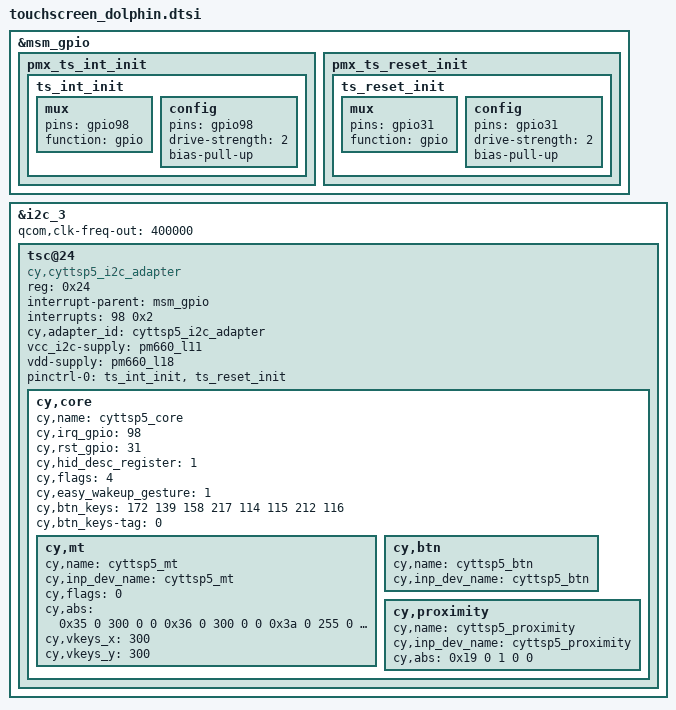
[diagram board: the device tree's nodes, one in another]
&msm_gpio {
	/* add pingrp for touchscreen */
	pmx_ts_int_init {
		ts_int_init: ts_int_init {
			mux {
				pins = "gpio98";
				function = "gpio";
			};

			config {
				pins = "gpio98";
				drive-strength = <2>;
				bias-pull-up;
			};
		};
	};

	pmx_ts_reset_init {
		ts_reset_init: ts_reset_init {
			mux {
				pins = "gpio31";
				function = "gpio";
			};

			config {
				pins = "gpio31";
				drive-strength = <2>;
				bias-pull-up;
			};
		};
	};
};

&i2c_3 {
	qcom,clk-freq-out = <400000>;
	status = "okay";

	/delete-node/ qcom,actuator@0;
	/delete-node/ qcom,eeprom@6c;
	/delete-node/ qcom,led-flash@60;
	/delete-node/ qcom,camera@0;
	/delete-node/ qcom,camera@1;
	/delete-node/ synaptics@20;

	tsc@24 {
		compatible = "cy,cyttsp5_i2c_adapter";
		reg = <0x24>;
		interrupt-parent = <&msm_gpio>;
		interrupts = <98 0x2>;
		cy,adapter_id = "cyttsp5_i2c_adapter";

		vcc_i2c-supply = <&pm660_l11>;
		vdd-supply = <&pm660_l18>;
		pinctrl-names = "pmx_ts_init";
		pinctrl-0 = <&ts_int_init &ts_reset_init>;

		cy,core {
			cy,name = "cyttsp5_core";

			cy,irq_gpio = <98>;
			cy,rst_gpio = <31>;
			cy,hid_desc_register = <1>;
			/* CY_CORE_FLAG_RESTORE_PARAMETERS */
			cy,flags = <4>;
			/* CY_CORE_EWG_NONE */
			cy,easy_wakeup_gesture = <1>;
			cy,btn_keys = <172 /* KEY_HOMEPAGE */
					   /* previously was KEY_HOME, new Android versions use KEY_HOMEPAGE */
				       139 /* KEY_MENU */
				       158 /* KEY_BACK */
				       217 /* KEY_SEARCH */
				       114 /* KEY_VOLUMEDOWN */
				       115 /* KEY_VOLUMEUP */
				       212 /* KEY_CAMERA */
				       116>; /* KEY_POWER */
			cy,btn_keys-tag = <0>;

			cy,mt {
				cy,name = "cyttsp5_mt";

				cy,inp_dev_name = "cyttsp5_mt";
				cy,flags = <0>;
				cy,abs =
					/* ABS_MT_POSITION_X, CY_ABS_MIN_X, CY_ABS_MAX_X, 0, 0 */
					<0x35 0 300 0 0
					/* ABS_MT_POSITION_Y, CY_ABS_MIN_Y, CY_ABS_MAX_Y, 0, 0 */
					0x36 0 300 0 0
					/* ABS_MT_PRESSURE, CY_ABS_MIN_P, CY_ABS_MAX_P, 0, 0 */
					0x3a 0 255 0 0
					/* CY_IGNORE_VALUE, CY_ABS_MIN_W, CY_ABS_MAX_W, 0, 0 */
					0xffff 0 255 0 0
					/* ABS_MT_TRACKING_ID, CY_ABS_MIN_T, CY_ABS_MAX_T, 0, 0 */
					0x39 0 3 0 0
					/* ABS_MT_TOUCH_MAJOR, 0, 255, 0, 0 */
					0x30 0 255 0 0
					/* ABS_MT_TOUCH_MINOR, 0, 255, 0, 0 */
					0x31 0 255 0 0
					/* ABS_MT_ORIENTATION, -127, 127, 0, 0 */
					0x34 0xffffff81 127 0 0
					/* ABS_MT_TOOL_TYPE, 0, MT_TOOL_MAX, 0, 0 */
					0x37 0 1 0 0
					/* ABS_DISTANCE, 0, 255, 0, 0 */
					0x19 0 255 0 0>;

				cy,vkeys_x = <300>;
				cy,vkeys_y = <300>;
			};
			cy,btn {
				cy,name = "cyttsp5_btn";

				cy,inp_dev_name = "cyttsp5_btn";
			};

			cy,proximity {
				cy,name = "cyttsp5_proximity";

				cy,inp_dev_name = "cyttsp5_proximity";
				cy,abs =
					/* ABS_DISTANCE, CY_PROXIMITY_MIN_VAL, CY_PROXIMITY_MAX_VAL, 0, 0 */
					<0x19 0 1 0 0>;
			};
		};
	};
};

